AUTOSAR XML (schema 4-2-2)
package /Components
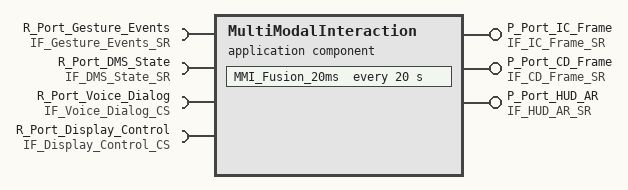
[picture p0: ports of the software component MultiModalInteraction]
  application sw component type MultiModalInteraction
    provide port P_Port_IC_Frame: provided-interface=IF_IC_Frame_SR
    provide port P_Port_CD_Frame: provided-interface=IF_CD_Frame_SR
    provide port P_Port_HUD_AR: provided-interface=IF_HUD_AR_SR
    4 x require port:
      R_Port_Gesture_Events: required-interface=IF_Gesture_Events_SR
      R_Port_DMS_State: required-interface=IF_DMS_State_SR
      R_Port_Voice_Dialog: required-interface=IF_Voice_Dialog_CS
      R_Port_Display_Control: required-interface=IF_Display_Control_CS
    behavior MultiModalInteraction_InternalBehavior
      asynchronous server call returns event MMI_Voice_Returned: start-on-event=MMI_Voice_Client, event-source=ASCRP_Get_Response_Result
      data received event MMI_Gesture_Received: start-on-event=MMI_Fusion_20ms
      data received event MMI_DMS_Received: start-on-event=MMI_Fusion_20ms
      init event MMI_Init_Event: start-on-event=MMI_Init
      timing event MMI_Fusion_Tick: start-on-event=MMI_Fusion_20ms, period=20
      4 x runnable:
        MMI_Init
          parameter access PA_Load_UI_Theme: accessed-parameter=P_Port_IC_Frame.Theme_Id
          parameter access PA_Load_HUD_Config: accessed-parameter=P_Port_HUD_AR.AR_Nav_Overlay
        MMI_Fusion_20ms: minimum-start-interval=20
          data-read-access:
            7 x access:
              VA_Read_Gesture_Type: accessed-variable=R_Port_Gesture_Events.Gesture_Type
              VA_Read_Gesture_Confidence: accessed-variable=R_Port_Gesture_Events.Gesture_Confidence
              VA_Read_Gesture_Timestamp: accessed-variable=R_Port_Gesture_Events.Timestamp
              VA_Read_DMS_Attention: accessed-variable=R_Port_DMS_State.Driver_Attention
              VA_Read_DMS_Drowsiness: accessed-variable=R_Port_DMS_State.Drowsiness_Level
              VA_Read_DMS_EyesOffRoad: accessed-variable=R_Port_DMS_State.Eyes_Off_Road
              VA_Read_DMS_Timestamp: accessed-variable=R_Port_DMS_State.Timestamp
        MMI_Render_Dispatch: minimum-start-interval=16
          data-send-points:
            9 x access:
              VA_Send_IC_Frame: accessed-variable=P_Port_IC_Frame.IC_Frame
              VA_Send_IC_Theme: accessed-variable=P_Port_IC_Frame.Theme_Id
              VA_Send_IC_Timestamp: accessed-variable=P_Port_IC_Frame.Timestamp
              VA_Send_CD_Frame: accessed-variable=P_Port_CD_Frame.CD_Frame
              VA_Send_CD_Layer_Composition: accessed-variable=P_Port_CD_Frame.Layer_Composition
              VA_Send_CD_Timestamp: accessed-variable=P_Port_CD_Frame.Timestamp
              VA_Send_HUD_Frame: accessed-variable=P_Port_HUD_AR.HUD_Frame
              VA_Send_AR_Nav_Overlay: accessed-variable=P_Port_HUD_AR.AR_Nav_Overlay
              VA_Send_HUD_Timestamp: accessed-variable=P_Port_HUD_AR.Timestamp
          async call ASCP_Set_Display_Mode: operation=R_Port_Display_Control.Set_Mode, timeout=100
        MMI_Voice_Client: minimum-start-interval=50, can-be-invoked-concurrently=true
          asynchronous server call result point ASCRP_Process_Utterance_Result: asynchronous-server-call-point=ASCP_Process_Utterance
          asynchronous server call result point ASCRP_Get_Response_Result: asynchronous-server-call-point=ASCP_Get_Response
          async call ASCP_Process_Utterance: operation=R_Port_Voice_Dialog.Process_Utterance, timeout=300
          async call ASCP_Get_Response: operation=R_Port_Voice_Dialog.Get_Response, timeout=300
